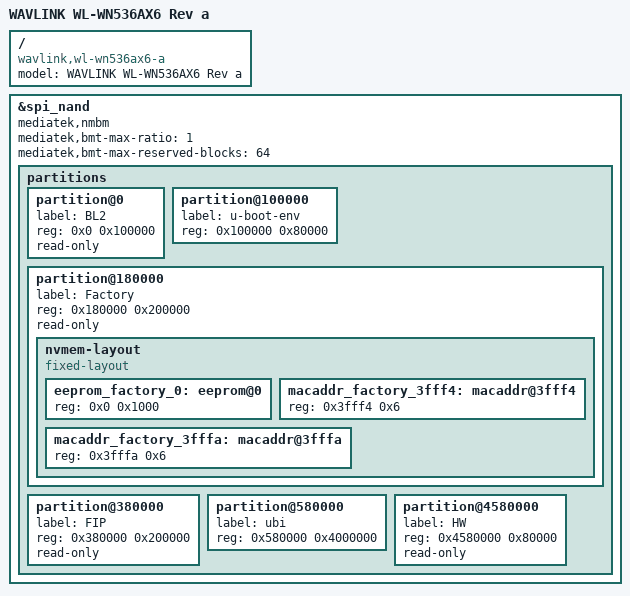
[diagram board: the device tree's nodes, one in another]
// SPDX-License-Identifier: (GPL-2.0-or-later OR MIT)

#include "mt7986a-wavlink-wl-wn536ax6-a-common.dtsi"

/ {
	compatible = "wavlink,wl-wn536ax6-a", "mediatek,mt7986a";
	model = "WAVLINK WL-WN536AX6 Rev a";
};

&spi_nand {
	mediatek,nmbm;
	mediatek,bmt-max-ratio = <1>;
	mediatek,bmt-max-reserved-blocks = <64>;

	partitions {
		partition@0 {
			label = "BL2";
			reg = <0x0 0x100000>;
			read-only;
		};

		partition@100000 {
			label = "u-boot-env";
			reg = <0x100000 0x80000>;
		};

		partition@180000 {
			label = "Factory";
			reg = <0x180000 0x200000>;
			read-only;

			nvmem-layout {
				compatible = "fixed-layout";
				#address-cells = <1>;
				#size-cells = <1>;

				eeprom_factory_0: eeprom@0 {
					reg = <0x0 0x1000>;
				};

				macaddr_factory_3fff4: macaddr@3fff4 {
					reg = <0x3fff4 0x6>;
				};

				macaddr_factory_3fffa: macaddr@3fffa {
					reg = <0x3fffa 0x6>;
				};
			};
		};

		partition@380000 {
			label = "FIP";
			reg = <0x380000 0x200000>;
			read-only;
		};

		partition@580000 {
			label = "ubi";
			reg = <0x580000 0x4000000>;
		};

		partition@4580000 {
			label = "HW";
			reg = <0x4580000 0x80000>;
			read-only;
		};
	};
};
